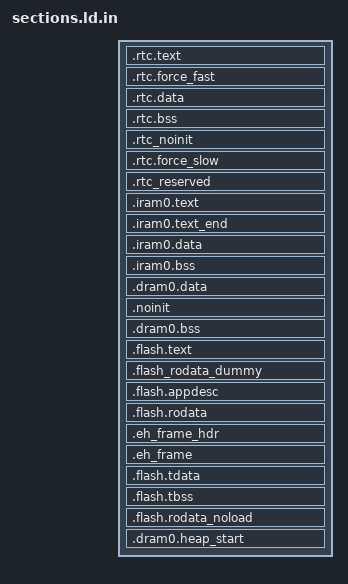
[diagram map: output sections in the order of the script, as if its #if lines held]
/*
 * SPDX-FileCopyrightText: 2022 Espressif Systems (Shanghai) CO LTD
 *
 * SPDX-License-Identifier: Apache-2.0
 */

#include "ld.common"

/* Default entry point */
ENTRY(call_start_cpu0);

SECTIONS
{
  /**
   * RTC fast memory holds RTC wake stub code,
   * including from any source file named rtc_wake_stub*.c
   */
  .rtc.text :
  {
    /* Align the start of RTC code region as per PMP granularity
     * this ensures we do not overwrite the permissions for the previous
     * region (ULP mem) regardless of its end alignment
     */
    ALIGNED_SYMBOL(_esp_pmp_align_size, _rtc_fast_start)
    ALIGNED_SYMBOL(_esp_pmp_align_size, _rtc_text_start)

    *(.rtc.entry.text)

    *(.rtc.literal .rtc.text .rtc.text.*)

    *rtc_wake_stub*.*(.text .text.*)
    *(.rtc_text_end_test)

    /* Align the end of RTC code region as per PMP granularity */
    . = ALIGN(_esp_pmp_align_size);

    _rtc_text_end = ABSOLUTE(.);
  } > lp_ram_seg

  /**
   * This section located in RTC FAST Memory area.
   * It holds data marked with RTC_FAST_ATTR attribute.
   * See the file "esp_attr.h" for more information.
   */
  .rtc.force_fast :
  {
    ALIGNED_SYMBOL(4, _rtc_force_fast_start)

    _coredump_rtc_fast_start = ABSOLUTE(.);
    *(.rtc.fast.coredump .rtc.fast.coredump.*)
    _coredump_rtc_fast_end = ABSOLUTE(.);

    *(.rtc.force_fast .rtc.force_fast.*)

    ALIGNED_SYMBOL(4, _rtc_force_fast_end)
  } > lp_ram_seg

  /**
   * RTC data section holds RTC wake stub
   * data/rodata, including from any source file
   * named rtc_wake_stub*.c and the data marked with
   * RTC_DATA_ATTR, RTC_RODATA_ATTR attributes.
   */
  .rtc.data :
  {
    _rtc_data_start = ABSOLUTE(.);

    _coredump_rtc_start = ABSOLUTE(.);
    *(.rtc.coredump .rtc.coredump.*)
    _coredump_rtc_end = ABSOLUTE(.);
    *(.rtc.data .rtc.data.*)
    *(.rtc.rodata .rtc.rodata.*)

    *rtc_wake_stub*.*(.data .rodata .data.* .rodata.* .srodata.*)

    _rtc_data_end = ABSOLUTE(.);
  } > lp_ram_seg

  /* RTC bss, from any source file named rtc_wake_stub*.c */
  .rtc.bss (NOLOAD) :
  {
    _rtc_bss_start = ABSOLUTE(.);

    *rtc_wake_stub*.*(.bss .bss.* .sbss .sbss.*)
    *rtc_wake_stub*.*(COMMON)

    _rtc_bss_end = ABSOLUTE(.);
    /* part that saves some data for rtc periph module, this part is
       only initialized at power on reset */
    _rtc_bss_rtc_start = ABSOLUTE(.);
    *(.rtc.bss .rtc.bss.*)
    _rtc_bss_rtc_end = ABSOLUTE(.);
  } > lp_ram_seg

  /**
   * This section holds data that should not be initialized at power up
   * and will be retained during deep sleep.
   * User data marked with RTC_NOINIT_ATTR will be placed
   * into this section. See the file "esp_attr.h" for more information.
   */
  .rtc_noinit (NOLOAD):
  {
    ALIGNED_SYMBOL(4, _rtc_noinit_start)

    *(.rtc_noinit .rtc_noinit.*)

    ALIGNED_SYMBOL(4, _rtc_noinit_end)
  } > lp_ram_seg

  /**
   * This section located in RTC SLOW Memory area.
   * It holds data marked with RTC_SLOW_ATTR attribute.
   * See the file "esp_attr.h" for more information.
   */
  .rtc.force_slow :
  {
    ALIGNED_SYMBOL(4, _rtc_force_slow_start)

    *(.rtc.force_slow .rtc.force_slow.*)

    ALIGNED_SYMBOL(4, _rtc_force_slow_end)
  } > lp_ram_seg

  /**
   * This section holds RTC data that should have fixed addresses.
   * The data are not initialized at power-up and are retained during deep
   * sleep.
   */
  .rtc_reserved (NOLOAD):
  {
    ALIGNED_SYMBOL(4, _rtc_reserved_start)

    /**
     * New data can only be added here to ensure existing data are not moved.
     * Because data have adhered to the end of the segment and code is relied
     * on it.
     * >> put new data here <<
     */

    *(.rtc_timer_data_in_rtc_mem .rtc_timer_data_in_rtc_mem.*)
    KEEP(*(.bootloader_data_rtc_mem .bootloader_data_rtc_mem.*))

    _rtc_reserved_end = ABSOLUTE(.);
  } > rtc_reserved_seg

  _rtc_reserved_length = _rtc_reserved_end - _rtc_reserved_start;
  ASSERT((_rtc_reserved_length <= LENGTH(rtc_reserved_seg)),
          "RTC reserved segment data does not fit.")

  /* Get size of rtc slow data based on rtc_data_location alias */
  _rtc_slow_length = (ORIGIN(rtc_slow_seg) == ORIGIN(rtc_data_location))
                        ? (_rtc_force_slow_end - _rtc_data_start)
                        : (_rtc_force_slow_end - _rtc_force_slow_start);

  _rtc_fast_length = (ORIGIN(rtc_slow_seg) == ORIGIN(rtc_data_location))
                        ? (_rtc_force_fast_end - _rtc_fast_start)
                        : (_rtc_noinit_end - _rtc_fast_start);

  ASSERT((_rtc_slow_length <= LENGTH(rtc_slow_seg)),
          "RTC_SLOW segment data does not fit.")

  ASSERT((_rtc_fast_length <= LENGTH(rtc_data_seg)),
          "RTC_FAST segment data does not fit.")

  .iram0.text :
  {
    _iram_start = ABSOLUTE(.);

#if CONFIG_ESP_DEBUG_INCLUDE_OCD_STUB_BINS
    /* Do not move this block! OpenOCD expects this to be at the beginning of IRAM. */
    KEEP(*(.ocd_stub.code));
    KEEP(*(.ocd_stub.tramp));
    . = ALIGN(0x800);
    KEEP(*(.ocd_stub.data));
    KEEP(*(.ocd_stub.bss));
    KEEP(*(.ocd_stub.stack));
    KEEP(*(.ocd_stub.params));
    . = ALIGN(0x1000);
    KEEP(*(.ocd_stub.scratchmem));
    ASSERT(ABSOLUTE(.) == _iram_start + 0x2000, "openocd stub memory must be ended at _iram_start + 0x2000");
#endif

    /* Vectors go to start of IRAM */
    ASSERT(ABSOLUTE(.) % 0x100 == 0, "vector address must be 256 byte aligned");
    KEEP(*(.exception_vectors_table.text));
    KEEP(*(.exception_vectors.text));

    ALIGNED_SYMBOL(4, _invalid_pc_placeholder)

    /* Code marked as running out of IRAM */
    _iram_text_start = ABSOLUTE(.);

    *(.iram1 .iram1.*)
    /* BEGIN generated from ESP-IDF linker fragments, do not edit */
    *libble_app.a:(.high_perf_code_iram1 .high_perf_code_iram1.*)
    *libble_app.a:(.iram_single_sleep .iram_single_sleep.*)
    *components/bt/*.*(.high_perf_code_iram1 .high_perf_code_iram1.*)
    *components/bt/*.*(.iram_single_sleep .iram_single_sleep.*)
    *libclang_rt.builtins.a:_divsf3.*(.literal .literal.* .text .text.*)
    *libclang_rt.builtins.a:restore.*(.literal .literal.* .text .text.*)
    *libclang_rt.builtins.a:save.*(.literal .literal.* .text .text.*)
    *libcoexist.a:(.coexiram .coexiram.*)
    *libcoexist.a:(.coexsleepiram .coexsleepiram.*)
    *components/esp_driver_dma/*esp_dma_utils.*(.literal.esp_dma_merge_aligned_rx_buffers .text.esp_dma_merge_aligned_rx_buffers)
    *components/esp_driver_dma/*esp_dma_utils.*(.literal.esp_dma_split_rx_buffer_to_cache_aligned .text.esp_dma_split_rx_buffer_to_cache_aligned)
    *components/esp_driver_dma/*gdma_link.*(.literal.gdma_link_concat .text.gdma_link_concat)
    *components/esp_driver_dma/*gdma_link.*(.literal.gdma_link_get_buffer .text.gdma_link_get_buffer)
    *components/esp_driver_dma/*gdma_link.*(.literal.gdma_link_get_head_addr .text.gdma_link_get_head_addr)
    *components/esp_driver_dma/*gdma_link.*(.literal.gdma_link_get_length .text.gdma_link_get_length)
    *components/esp_driver_dma/*gdma_link.*(.literal.gdma_link_mount_buffers .text.gdma_link_mount_buffers)
    *components/esp_driver_rmt/*rmt_encoder.*(.literal.rmt_encoder_reset .text.rmt_encoder_reset)
    *components/esp_driver_rmt/*rmt_tx.*(.literal.rmt_encode_check_result .text.rmt_encode_check_result)
    *components/esp_driver_rmt/*rmt_tx.*(.literal.rmt_isr_handle_tx_done .text.rmt_isr_handle_tx_done)
    *components/esp_driver_rmt/*rmt_tx.*(.literal.rmt_isr_handle_tx_loop_end .text.rmt_isr_handle_tx_loop_end)
    *components/esp_driver_rmt/*rmt_tx.*(.literal.rmt_isr_handle_tx_threshold .text.rmt_isr_handle_tx_threshold)
    *components/esp_driver_rmt/*rmt_tx.*(.literal.rmt_tx_default_isr .text.rmt_tx_default_isr)
    *components/esp_driver_rmt/*rmt_tx.*(.literal.rmt_tx_do_transaction .text.rmt_tx_do_transaction)
    *components/esp_driver_rmt/*rmt_tx.*(.literal.rmt_tx_mark_eof .text.rmt_tx_mark_eof)
    *components/esp_hal_ana_conv/*temperature_sensor_hal.*(.literal.temperature_sensor_hal_get_raw_value .text.temperature_sensor_hal_get_raw_value)
    *components/esp_hal_ana_conv/*temperature_sensor_hal.*(.literal.temperature_sensor_hal_i2c_saradc_reg_backup .text.temperature_sensor_hal_i2c_saradc_reg_backup)
    *components/esp_hal_ana_conv/*temperature_sensor_hal.*(.literal.temperature_sensor_hal_i2c_saradc_reg_restore .text.temperature_sensor_hal_i2c_saradc_reg_restore)
    *components/esp_hal_dma/*gdma_hal_ahb_v1.*(.literal.gdma_ahb_hal_append .text.gdma_ahb_hal_append)
    *components/esp_hal_dma/*gdma_hal_ahb_v1.*(.literal.gdma_ahb_hal_clear_intr .text.gdma_ahb_hal_clear_intr)
    *components/esp_hal_dma/*gdma_hal_ahb_v1.*(.literal.gdma_ahb_hal_get_eof_desc_addr .text.gdma_ahb_hal_get_eof_desc_addr)
    *components/esp_hal_dma/*gdma_hal_ahb_v1.*(.literal.gdma_ahb_hal_is_tx_link_switch_event_supported .text.gdma_ahb_hal_is_tx_link_switch_event_supported)
    *components/esp_hal_dma/*gdma_hal_ahb_v1.*(.literal.gdma_ahb_hal_read_intr_status .text.gdma_ahb_hal_read_intr_status)
    *components/esp_hal_dma/*gdma_hal_ahb_v1.*(.literal.gdma_ahb_hal_reset .text.gdma_ahb_hal_reset)
    *components/esp_hal_dma/*gdma_hal_ahb_v1.*(.literal.gdma_ahb_hal_start_with_desc .text.gdma_ahb_hal_start_with_desc)
    *components/esp_hal_dma/*gdma_hal_ahb_v1.*(.literal.gdma_ahb_hal_stop .text.gdma_ahb_hal_stop)
    *components/esp_hal_dma/*gdma_hal_top.*(.literal.gdma_hal_append .text.gdma_hal_append)
    *components/esp_hal_dma/*gdma_hal_top.*(.literal.gdma_hal_clear_intr .text.gdma_hal_clear_intr)
    *components/esp_hal_dma/*gdma_hal_top.*(.literal.gdma_hal_get_eof_desc_addr .text.gdma_hal_get_eof_desc_addr)
    *components/esp_hal_dma/*gdma_hal_top.*(.literal.gdma_hal_is_tx_link_switch_event_supported .text.gdma_hal_is_tx_link_switch_event_supported)
    *components/esp_hal_dma/*gdma_hal_top.*(.literal.gdma_hal_read_intr_status .text.gdma_hal_read_intr_status)
    *components/esp_hal_dma/*gdma_hal_top.*(.literal.gdma_hal_reset .text.gdma_hal_reset)
    *components/esp_hal_dma/*gdma_hal_top.*(.literal.gdma_hal_start_with_desc .text.gdma_hal_start_with_desc)
    *components/esp_hal_dma/*gdma_hal_top.*(.literal.gdma_hal_stop .text.gdma_hal_stop)
    *components/esp_hal_gpio/*gpio_hal.*(.literal.gpio_hal_isolate_in_sleep .text.gpio_hal_isolate_in_sleep)
    *components/esp_hal_gpspi/*spi_hal_iram.*(.literal .literal.* .text .text.*)
    *components/esp_hal_gpspi/*spi_slave_hal_iram.*(.literal .literal.* .text .text.*)
    *components/esp_hal_i2c/*i2c_hal_iram.*(.literal .literal.* .text .text.*)
    *components/esp_hal_ledc/*ledc_hal_iram.*(.literal .literal.* .text .text.*)
    *components/esp_hal_mspi/*spi_flash_encrypt_hal_iram.*(.literal .literal.* .text .text.*)
    *components/esp_hal_mspi/*spi_flash_hal_gpspi.*(.literal .literal.* .text .text.*)
    *components/esp_hal_mspi/*spi_flash_hal_iram.*(.literal .literal.* .text .text.*)
    *components/esp_hal_pmu/*pmu_hal.*(.literal .literal.* .text .text.*)
    *components/esp_hal_regi2c/*.*(.literal .literal.* .text .text.*)
    *components/esp_hal_systimer/*.*(.literal .literal.* .text .text.*)
    *components/esp_hal_timg/*timer_hal.*(.literal.timer_hal_capture_and_get_counter_value .text.timer_hal_capture_and_get_counter_value)
    *components/esp_hal_wdt/*rom_patch.*(.literal .literal.* .text .text.*)
    *components/esp_hw_support/*adc_share_hw_ctrl.*(.literal.adc_apb_periph_claim .text.adc_apb_periph_claim)
    *components/esp_hw_support/*adc_share_hw_ctrl.*(.literal.adc_apb_periph_free .text.adc_apb_periph_free)
    *components/esp_hw_support/*clk_utils.*(.literal .literal.* .text .text.*)
    *components/esp_hw_support/*cpu.*(.literal.esp_cpu_compare_and_set .text.esp_cpu_compare_and_set)
    *components/esp_hw_support/*cpu.*(.literal.esp_cpu_reset .text.esp_cpu_reset)
    *components/esp_hw_support/*cpu.*(.literal.esp_cpu_stall .text.esp_cpu_stall)
    *components/esp_hw_support/*cpu.*(.literal.esp_cpu_unstall .text.esp_cpu_unstall)
    *components/esp_hw_support/*cpu.*(.literal.esp_cpu_wait_for_intr .text.esp_cpu_wait_for_intr)
    *components/esp_hw_support/*esp_clk.*(.literal.esp_clk_private_lock .text.esp_clk_private_lock)
    *components/esp_hw_support/*esp_clk.*(.literal.esp_clk_private_unlock .text.esp_clk_private_unlock)
    *components/esp_hw_support/*esp_clk.*(.literal.esp_clk_slowclk_cal_get .text.esp_clk_slowclk_cal_get)
    *components/esp_hw_support/*esp_clk.*(.literal.esp_clk_slowclk_cal_set .text.esp_clk_slowclk_cal_set)
    *components/esp_hw_support/*esp_clk.*(.literal.esp_rtc_get_time_us .text.esp_rtc_get_time_us)
    *components/esp_hw_support/*esp_clk_tree.*(.literal.esp_clk_tree_enable_power .text.esp_clk_tree_enable_power)
    *components/esp_hw_support/*esp_clk_tree.*(.literal.esp_clk_tree_enable_src .text.esp_clk_tree_enable_src)
    *components/esp_hw_support/*esp_clk_tree.*(.literal.esp_clk_tree_is_power_on .text.esp_clk_tree_is_power_on)
    *components/esp_hw_support/*esp_memory_utils.*(.literal .literal.* .text .text.*)
    *components/esp_hw_support/*mspi_timing_tuning.*(.literal .literal.* .text .text.*)
    *components/esp_hw_support/*periph_ctrl.*(.literal.periph_module_reset .text.periph_module_reset)
    *components/esp_hw_support/*periph_ctrl.*(.literal.periph_rcc_acquire_enter .text.periph_rcc_acquire_enter)
    *components/esp_hw_support/*periph_ctrl.*(.literal.periph_rcc_acquire_exit .text.periph_rcc_acquire_exit)
    *components/esp_hw_support/*periph_ctrl.*(.literal.periph_rcc_enter .text.periph_rcc_enter)
    *components/esp_hw_support/*periph_ctrl.*(.literal.periph_rcc_exit .text.periph_rcc_exit)
    *components/esp_hw_support/*periph_ctrl.*(.literal.periph_rcc_release_enter .text.periph_rcc_release_enter)
    *components/esp_hw_support/*periph_ctrl.*(.literal.periph_rcc_release_exit .text.periph_rcc_release_exit)
    *components/esp_hw_support/*peripheral_domain_pd.*(.literal.peripheral_domain_pd_allowed .text.peripheral_domain_pd_allowed)
    *components/esp_hw_support/*pmu_param.*(.literal.get_act_hp_dbias .text.get_act_hp_dbias)
    *components/esp_hw_support/*pmu_param.*(.literal.get_act_lp_dbias .text.get_act_lp_dbias)
    *components/esp_hw_support/*pmu_sleep.*(.literal .literal.* .text .text.*)
    *components/esp_hw_support/*regi2c_ctrl.*(.literal .literal.* .text .text.*)
    *components/esp_hw_support/*rtc_clk.*(.literal .literal.* .text .text.*)
    *components/esp_hw_support/*rtc_time.*(.literal .literal.* .text .text.*)
    *components/esp_hw_support/*sar_periph_ctrl.*(.literal.adc_reset_lock_acquire .text.adc_reset_lock_acquire)
    *components/esp_hw_support/*sar_periph_ctrl.*(.literal.adc_reset_lock_release .text.adc_reset_lock_release)
    *components/esp_hw_support/*sar_periph_ctrl.*(.literal.sar_periph_ctrl_adc_reset .text.sar_periph_ctrl_adc_reset)
    *components/esp_hw_support/*sar_periph_ctrl.*(.literal.sar_periph_ctrl_power_disable .text.sar_periph_ctrl_power_disable)
    *components/esp_hw_support/*sar_periph_ctrl.*(.literal.sar_periph_ctrl_power_enable .text.sar_periph_ctrl_power_enable)
    *components/esp_hw_support/*sar_periph_ctrl_common.*(.literal.regi2c_saradc_disable .text.regi2c_saradc_disable)
    *components/esp_hw_support/*sar_periph_ctrl_common.*(.literal.regi2c_saradc_enable .text.regi2c_saradc_enable)
    *components/esp_hw_support/*sar_tsens_ctrl.*(.literal.temp_sensor_get_raw_value .text.temp_sensor_get_raw_value)
    *components/esp_hw_support/*sar_tsens_ctrl.*(.literal.temperature_sensor_power_acquire .text.temperature_sensor_power_acquire)
    *components/esp_hw_support/*sar_tsens_ctrl.*(.literal.temperature_sensor_power_release .text.temperature_sensor_power_release)
    *components/esp_hw_support/*sleep_cache.*(.literal .literal.* .text .text.*)
    *components/esp_hw_support/*sleep_clock.*(.literal.clock_domain_pd_allowed .text.clock_domain_pd_allowed)
    *components/esp_hw_support/*sleep_console.*(.literal .literal.* .text .text.*)
    *components/esp_hw_support/*sleep_cpu.*(.literal.cpu_domain_pd_allowed .text.cpu_domain_pd_allowed)
    *components/esp_hw_support/*sleep_modem.*(.literal.modem_domain_pd_allowed .text.modem_domain_pd_allowed)
    *components/esp_hw_support/*sleep_modem.*(.literal.periph_inform_out_light_sleep_overhead .text.periph_inform_out_light_sleep_overhead)
    *components/esp_hw_support/*sleep_modem.*(.literal.sleep_modem_reject_triggers .text.sleep_modem_reject_triggers)
    *components/esp_hw_support/*sleep_modes.*(.literal.esp_light_sleep_start .text.esp_light_sleep_start)
    *components/esp_hw_support/*sleep_modes.*(.literal.esp_sleep_enable_timer_wakeup .text.esp_sleep_enable_timer_wakeup)
    *components/esp_hw_support/*sleep_mspi.*(.literal .literal.* .text .text.*)
    *components/esp_hw_support/*systimer.*(.literal .literal.* .text .text.*)
    *components/esp_libc/*abort.*(.literal .literal.* .text .text.*)
    *components/esp_libc/*assert.*(.literal .literal.* .text .text.*)
    *components/esp_libc/*esp_time_impl.*(.literal.esp_set_time_from_rtc .text.esp_set_time_from_rtc)
    *components/esp_libc/*esp_time_impl.*(.literal.esp_time_impl_get_boot_time .text.esp_time_impl_get_boot_time)
    *components/esp_libc/*esp_time_impl.*(.literal.esp_time_impl_set_boot_time .text.esp_time_impl_set_boot_time)
    *components/esp_libc/*heap.*(.literal .literal.* .text .text.*)
    *components/esp_libc/*memcmp.*(.literal .literal.* .text .text.*)
    *components/esp_libc/*memcpy.*(.literal .literal.* .text .text.*)
    *components/esp_libc/*memmove.*(.literal .literal.* .text .text.*)
    *components/esp_libc/*stdatomic.*(.literal .literal.* .text .text.*)
    *components/esp_libc/*strcmp.*(.literal .literal.* .text .text.*)
    *components/esp_libc/*strcpy.*(.literal .literal.* .text .text.*)
    *components/esp_libc/*strncmp.*(.literal .literal.* .text .text.*)
    *components/esp_libc/*strncpy.*(.literal .literal.* .text .text.*)
    *components/esp_mm/*esp_cache_msync.*(.literal .literal.* .text .text.*)
    *components/esp_mm/*esp_cache_utils.*(.literal .literal.* .text .text.*)
    *components/esp_phy/*phy_init.*(.literal.esp_phy_disable .text.esp_phy_disable)
    *components/esp_phy/*phy_init.*(.literal.esp_phy_enable .text.esp_phy_enable)
    *components/esp_phy/*phy_init.*(.literal.esp_wifi_bt_power_domain_off .text.esp_wifi_bt_power_domain_off)
    *components/esp_phy/*phy_override.*(.literal.phy_get_tsens_value .text.phy_get_tsens_value)
    *components/esp_pm/*pm_impl.*(.literal.esp_pm_impl_get_cpu_freq .text.esp_pm_impl_get_cpu_freq)
    *components/esp_rom/*esp_rom_print.*(.literal .literal.* .text .text.*)
    *components/esp_rom/*esp_rom_spiflash.*(.literal .literal.* .text .text.*)
    *components/esp_rom/*esp_rom_sys.*(.literal .literal.* .text .text.*)
    *components/esp_system/*esp_err.*(.literal .literal.* .text .text.*)
    *components/esp_system/*image_process.*(.literal .literal.* .text .text.*)
    *components/esp_system/*ubsan.*(.literal .literal.* .text .text.*)
    *components/esp_timer/*esp_timer_impl_common.*(.literal.esp_timer_impl_lock .text.esp_timer_impl_lock)
    *components/esp_timer/*esp_timer_impl_common.*(.literal.esp_timer_impl_unlock .text.esp_timer_impl_unlock)
    *components/esp_timer/*esp_timer_impl_systimer.*(.literal.esp_timer_impl_advance .text.esp_timer_impl_advance)
    *components/esp_timer/*esp_timer_impl_systimer.*(.literal.esp_timer_impl_set .text.esp_timer_impl_set)
    *components/esp_wifi/*esp_adapter.*(.literal.coex_pti_get_wrapper .text.coex_pti_get_wrapper)
    *components/esp_wifi/*esp_adapter.*(.literal.wifi_clock_disable_wrapper .text.wifi_clock_disable_wrapper)
    *components/esp_wifi/*esp_adapter.*(.literal.wifi_clock_enable_wrapper .text.wifi_clock_enable_wrapper)
    *components/freertos/*port_systick.*(.literal .literal.* .text .text.*)
    *components/freertos/*portasm.*(.literal .literal.* .text .text.*)
    *libgcc.a:_divsf3.*(.literal .literal.* .text .text.*)
    *libgcc.a:lib2funcs.*(.literal .literal.* .text .text.*)
    *libgcc.a:save-restore.*(.literal .literal.* .text .text.*)
    *libgcov.a:(.literal .literal.* .text .text.*)
    *components/hal/*cache_hal.*(.literal .literal.* .text .text.*)
    *components/hal/*mmu_hal.*(.literal .literal.* .text .text.*)
    *components/heap/*multi_heap.*(.literal.multi_heap_aligned_alloc_offs .text.multi_heap_aligned_alloc_offs)
    *components/heap/*multi_heap.*(.literal.multi_heap_get_full_block_size .text.multi_heap_get_full_block_size)
    *components/ieee802154/*esp_ieee802154.*(.literal.esp_ieee802154_enh_ack_generator .text.esp_ieee802154_enh_ack_generator)
    *components/ieee802154/*esp_ieee802154.*(.literal.esp_ieee802154_get_extended_address .text.esp_ieee802154_get_extended_address)
    *components/ieee802154/*esp_ieee802154.*(.literal.esp_ieee802154_get_recent_lqi .text.esp_ieee802154_get_recent_lqi)
    *components/ieee802154/*esp_ieee802154.*(.literal.esp_ieee802154_get_recent_rssi .text.esp_ieee802154_get_recent_rssi)
    *components/ieee802154/*esp_ieee802154.*(.literal.esp_ieee802154_receive .text.esp_ieee802154_receive)
    *components/ieee802154/*esp_ieee802154.*(.literal.esp_ieee802154_receive_at .text.esp_ieee802154_receive_at)
    *components/ieee802154/*esp_ieee802154.*(.literal.esp_ieee802154_set_transmit_security .text.esp_ieee802154_set_transmit_security)
    *components/ieee802154/*esp_ieee802154.*(.literal.esp_ieee802154_transmit .text.esp_ieee802154_transmit)
    *components/ieee802154/*esp_ieee802154.*(.literal.esp_ieee802154_transmit_at .text.esp_ieee802154_transmit_at)
    *components/ieee802154/*esp_ieee802154_ack.*(.literal.ieee802154_ack_config_pending_bit .text.ieee802154_ack_config_pending_bit)
    *components/ieee802154/*esp_ieee802154_dev.*(.literal.ieee802154_finish_receive_at .text.ieee802154_finish_receive_at)
    *components/ieee802154/*esp_ieee802154_dev.*(.literal.ieee802154_get_recent_lqi .text.ieee802154_get_recent_lqi)
    *components/ieee802154/*esp_ieee802154_dev.*(.literal.ieee802154_get_recent_rssi .text.ieee802154_get_recent_rssi)
    *components/ieee802154/*esp_ieee802154_dev.*(.literal.ieee802154_isr .text.ieee802154_isr)
    *components/ieee802154/*esp_ieee802154_dev.*(.literal.ieee802154_receive .text.ieee802154_receive)
    *components/ieee802154/*esp_ieee802154_dev.*(.literal.ieee802154_receive_at .text.ieee802154_receive_at)
    *components/ieee802154/*esp_ieee802154_dev.*(.literal.ieee802154_rx_frame_info_update .text.ieee802154_rx_frame_info_update)
    *components/ieee802154/*esp_ieee802154_dev.*(.literal.ieee802154_start_receive_at .text.ieee802154_start_receive_at)
    *components/ieee802154/*esp_ieee802154_dev.*(.literal.ieee802154_transmit .text.ieee802154_transmit)
    *components/ieee802154/*esp_ieee802154_dev.*(.literal.ieee802154_transmit_at .text.ieee802154_transmit_at)
    *components/ieee802154/*esp_ieee802154_dev.*(.literal.set_next_rx_buffer .text.set_next_rx_buffer)
    *components/ieee802154/*esp_ieee802154_dev.*(.literal.stop_cca .text.stop_cca)
    *components/ieee802154/*esp_ieee802154_dev.*(.literal.stop_current_operation .text.stop_current_operation)
    *components/ieee802154/*esp_ieee802154_dev.*(.literal.stop_ed .text.stop_ed)
    *components/ieee802154/*esp_ieee802154_dev.*(.literal.stop_rx .text.stop_rx)
    *components/ieee802154/*esp_ieee802154_dev.*(.literal.stop_rx_ack .text.stop_rx_ack)
    *components/ieee802154/*esp_ieee802154_dev.*(.literal.stop_tx .text.stop_tx)
    *components/ieee802154/*esp_ieee802154_dev.*(.literal.stop_tx_ack .text.stop_tx_ack)
    *components/ieee802154/*esp_ieee802154_dev.*(.literal.stop_tx_cca .text.stop_tx_cca)
    *components/ieee802154/*esp_ieee802154_event.*(.literal.ieee802154_inner_energy_detect_done .text.ieee802154_inner_energy_detect_done)
    *components/ieee802154/*esp_ieee802154_event.*(.literal.ieee802154_inner_enh_ack_generator .text.ieee802154_inner_enh_ack_generator)
    *components/ieee802154/*esp_ieee802154_event.*(.literal.ieee802154_inner_receive_done .text.ieee802154_inner_receive_done)
    *components/ieee802154/*esp_ieee802154_event.*(.literal.ieee802154_inner_receive_sfd_done .text.ieee802154_inner_receive_sfd_done)
    *components/ieee802154/*esp_ieee802154_event.*(.literal.ieee802154_inner_transmit_done .text.ieee802154_inner_transmit_done)
    *components/ieee802154/*esp_ieee802154_event.*(.literal.ieee802154_inner_transmit_failed .text.ieee802154_inner_transmit_failed)
    *components/ieee802154/*esp_ieee802154_event.*(.literal.ieee802154_inner_transmit_sfd_done .text.ieee802154_inner_transmit_sfd_done)
    *components/ieee802154/*esp_ieee802154_frame.*(.literal.ieee802154_frame_get_dest_panid .text.ieee802154_frame_get_dest_panid)
    *components/ieee802154/*esp_ieee802154_frame.*(.literal.ieee802154_frame_get_dst_addr .text.ieee802154_frame_get_dst_addr)
    *components/ieee802154/*esp_ieee802154_frame.*(.literal.ieee802154_frame_get_security_field_len .text.ieee802154_frame_get_security_field_len)
    *components/ieee802154/*esp_ieee802154_frame.*(.literal.ieee802154_frame_get_security_payload_offset .text.ieee802154_frame_get_security_payload_offset)
    *components/ieee802154/*esp_ieee802154_frame.*(.literal.ieee802154_frame_get_src_addr .text.ieee802154_frame_get_src_addr)
    *components/ieee802154/*esp_ieee802154_frame.*(.literal.ieee802154_frame_get_src_panid .text.ieee802154_frame_get_src_panid)
    *components/ieee802154/*esp_ieee802154_frame.*(.literal.ieee802154_frame_is_security_enabled .text.ieee802154_frame_is_security_enabled)
    *components/ieee802154/*esp_ieee802154_frame.*(.literal.ieee802154_frame_security_header_offset .text.ieee802154_frame_security_header_offset)
    *components/ieee802154/*esp_ieee802154_frame.*(.literal.ieee802154_is_data_request .text.ieee802154_is_data_request)
    *components/ieee802154/*esp_ieee802154_frame.*(.literal.is_dst_panid_present .text.is_dst_panid_present)
    *components/ieee802154/*esp_ieee802154_frame.*(.literal.is_src_panid_present .text.is_src_panid_present)
    *components/ieee802154/*esp_ieee802154_pib.*(.literal.ieee802154_pib_get_pending_mode .text.ieee802154_pib_get_pending_mode)
    *components/ieee802154/*esp_ieee802154_pib.*(.literal.ieee802154_pib_get_rx_when_idle .text.ieee802154_pib_get_rx_when_idle)
    *components/ieee802154/*esp_ieee802154_pib.*(.literal.ieee802154_pib_update .text.ieee802154_pib_update)
    *components/ieee802154/*esp_ieee802154_pib.*(.literal.ieee802154_txpower_convert .text.ieee802154_txpower_convert)
    *components/ieee802154/*esp_ieee802154_sec.*(.literal.ieee802154_sec_clear .text.ieee802154_sec_clear)
    *components/ieee802154/*esp_ieee802154_sec.*(.literal.ieee802154_transmit_security_config .text.ieee802154_transmit_security_config)
    *components/ieee802154/*esp_ieee802154_timer.*(.literal.ieee802154_timer0_fire_at .text.ieee802154_timer0_fire_at)
    *components/ieee802154/*esp_ieee802154_timer.*(.literal.ieee802154_timer0_fire_at_with_callback .text.ieee802154_timer0_fire_at_with_callback)
    *components/ieee802154/*esp_ieee802154_timer.*(.literal.ieee802154_timer0_set_callback .text.ieee802154_timer0_set_callback)
    *components/ieee802154/*esp_ieee802154_timer.*(.literal.ieee802154_timer0_set_threshold .text.ieee802154_timer0_set_threshold)
    *components/ieee802154/*esp_ieee802154_timer.*(.literal.ieee802154_timer0_start .text.ieee802154_timer0_start)
    *components/ieee802154/*esp_ieee802154_timer.*(.literal.ieee802154_timer0_stop .text.ieee802154_timer0_stop)
    *components/ieee802154/*esp_ieee802154_timer.*(.literal.ieee802154_timer1_fire_at .text.ieee802154_timer1_fire_at)
    *components/ieee802154/*esp_ieee802154_timer.*(.literal.ieee802154_timer1_fire_at_with_callback .text.ieee802154_timer1_fire_at_with_callback)
    *components/ieee802154/*esp_ieee802154_timer.*(.literal.ieee802154_timer1_set_callback .text.ieee802154_timer1_set_callback)
    *components/ieee802154/*esp_ieee802154_timer.*(.literal.ieee802154_timer1_set_threshold .text.ieee802154_timer1_set_threshold)
    *components/ieee802154/*esp_ieee802154_timer.*(.literal.ieee802154_timer1_start .text.ieee802154_timer1_start)
    *components/ieee802154/*esp_ieee802154_timer.*(.literal.ieee802154_timer1_stop .text.ieee802154_timer1_stop)
    *components/ieee802154/*esp_ieee802154_timer.*(.literal.isr_handle_timer0_done .text.isr_handle_timer0_done)
    *components/ieee802154/*esp_ieee802154_timer.*(.literal.isr_handle_timer1_done .text.isr_handle_timer1_done)
    *components/ieee802154/*esp_ieee802154_util.*(.literal.ieee802154_channel_to_freq .text.ieee802154_channel_to_freq)
    *components/ieee802154/*esp_ieee802154_util.*(.literal.ieee802154_etm_channel_clear .text.ieee802154_etm_channel_clear)
    *components/log/*log.*(.literal .literal.* .text .text.*)
    *components/log/*log_format_text.*(.literal .literal.* .text .text.*)
    *components/log/*log_lock.*(.literal .literal.* .text .text.*)
    *components/log/*log_print.*(.literal .literal.* .text .text.*)
    *components/log/*log_timestamp.*(.literal.esp_log_early_timestamp .text.esp_log_early_timestamp)
    *components/log/*log_timestamp_common.*(.literal .literal.* .text .text.*)
    *components/log/*util.*(.literal .literal.* .text .text.*)
    *libnet80211.a:(.wifi0iram .wifi0iram.*)
    *libnet80211.a:(.wifiextrairam .wifiextrairam.*)
    *libnet80211.a:(.wifirxiram .wifirxiram.*)
    *libnet80211.a:(.wifislpiram .wifislpiram.*)
    *libnet80211.a:(.wifislprxiram .wifislprxiram.*)
    *libpp.a:(.wifi0iram .wifi0iram.*)
    *libpp.a:(.wifiextrairam .wifiextrairam.*)
    *libpp.a:(.wifiorslpiram .wifiorslpiram.*)
    *libpp.a:(.wifirxiram .wifirxiram.*)
    *libpp.a:(.wifislpiram .wifislpiram.*)
    *libpp.a:(.wifislprxiram .wifislprxiram.*)
    *components/riscv/*interrupt.*(.text .text._global_interrupt_handler .text.intr_get_item.part.0 .text.intr_handler_get_arg)
    *components/riscv/*rv_utils.*(.literal .literal.* .text .text.*)
    *components/riscv/*vectors.*(.literal .literal.* .text .text.*)
    *librtc.a:(.literal .literal.* .text .text.*)
    *components/soc/*lldesc.*(.literal .literal.* .text .text.*)
    *components/spi_flash/*esp_flash_api.*(.literal.check_chip_pointer_default .text.check_chip_pointer_default)
    *components/spi_flash/*esp_flash_api.*(.literal.detect_spi_flash_chip .text.detect_spi_flash_chip)
    *components/spi_flash/*esp_flash_api.*(.literal.esp_flash_chip_driver_initialized .text.esp_flash_chip_driver_initialized)
    *components/spi_flash/*esp_flash_api.*(.literal.esp_flash_erase_chip .text.esp_flash_erase_chip)
    *components/spi_flash/*esp_flash_api.*(.literal.esp_flash_erase_region .text.esp_flash_erase_region)
    *components/spi_flash/*esp_flash_api.*(.literal.esp_flash_get_chip_write_protect .text.esp_flash_get_chip_write_protect)
    *components/spi_flash/*esp_flash_api.*(.literal.esp_flash_get_io_mode .text.esp_flash_get_io_mode)
    *components/spi_flash/*esp_flash_api.*(.literal.esp_flash_get_physical_size .text.esp_flash_get_physical_size)
    *components/spi_flash/*esp_flash_api.*(.literal.esp_flash_get_protected_region .text.esp_flash_get_protected_region)
    *components/spi_flash/*esp_flash_api.*(.literal.esp_flash_get_size .text.esp_flash_get_size)
    *components/spi_flash/*esp_flash_api.*(.literal.esp_flash_init .text.esp_flash_init)
    *components/spi_flash/*esp_flash_api.*(.literal.esp_flash_init_main .text.esp_flash_init_main)
    *components/spi_flash/*esp_flash_api.*(.literal.esp_flash_is_quad_mode .text.esp_flash_is_quad_mode)
    *components/spi_flash/*esp_flash_api.*(.literal.esp_flash_read .text.esp_flash_read)
    *components/spi_flash/*esp_flash_api.*(.literal.esp_flash_read_encrypted .text.esp_flash_read_encrypted)
    *components/spi_flash/*esp_flash_api.*(.literal.esp_flash_set_chip_write_protect .text.esp_flash_set_chip_write_protect)
    *components/spi_flash/*esp_flash_api.*(.literal.esp_flash_set_io_mode .text.esp_flash_set_io_mode)
    *components/spi_flash/*esp_flash_api.*(.literal.esp_flash_set_protected_region .text.esp_flash_set_protected_region)
    *components/spi_flash/*esp_flash_api.*(.literal.esp_flash_write .text.esp_flash_write)
    *components/spi_flash/*esp_flash_api.*(.literal.esp_flash_write_encrypted .text.esp_flash_write_encrypted)
    *components/spi_flash/*esp_flash_api.*(.literal.flash_end_flush_cache .text.flash_end_flush_cache)
    *components/spi_flash/*esp_flash_api.*(.literal.read_unique_id .text.read_unique_id)
    *components/spi_flash/*esp_flash_api.*(.literal.spiflash_end_default .text.spiflash_end_default)
    *components/spi_flash/*esp_flash_api.*(.literal.spiflash_start_core .text.spiflash_start_core)
    *components/spi_flash/*esp_flash_api.*(.literal.spiflash_start_prog .text.spiflash_start_prog)
    *components/spi_flash/*flash_brownout_hook.*(.literal .literal.* .text .text.*)
    *components/spi_flash/*memspi_host_driver.*(.literal .literal.* .text .text.*)
    *components/spi_flash/*spi_flash_chip_boya.*(.literal .literal.* .text .text.*)
    *components/spi_flash/*spi_flash_chip_gd.*(.literal .literal.* .text .text.*)
    *components/spi_flash/*spi_flash_chip_generic.*(.literal .literal.* .text .text.*)
    *components/spi_flash/*spi_flash_chip_issi.*(.literal .literal.* .text .text.*)
    *components/spi_flash/*spi_flash_chip_mxic.*(.literal .literal.* .text .text.*)
    *components/spi_flash/*spi_flash_chip_th.*(.literal .literal.* .text .text.*)
    *components/spi_flash/*spi_flash_chip_winbond.*(.literal .literal.* .text .text.*)
    *components/spi_flash/*spi_flash_os_func_app.*(.literal.delay_us .text.delay_us)
    *components/spi_flash/*spi_flash_os_func_app.*(.literal.get_buffer_malloc .text.get_buffer_malloc)
    *components/spi_flash/*spi_flash_os_func_app.*(.literal.main_flash_region_protected .text.main_flash_region_protected)
    *components/spi_flash/*spi_flash_os_func_app.*(.literal.release_buffer_malloc .text.release_buffer_malloc)
    *components/spi_flash/*spi_flash_os_func_app.*(.literal.spi23_end .text.spi23_end)
    *components/spi_flash/*spi_flash_os_func_app.*(.literal.spi23_start .text.spi23_start)
    *components/spi_flash/*spi_flash_os_func_app.*(.literal.spi_flash_os_check_yield .text.spi_flash_os_check_yield)
    *components/spi_flash/*spi_flash_os_func_app.*(.literal.spi_flash_os_yield .text.spi_flash_os_yield)
    *components/spi_flash/*spi_flash_os_func_noos.*(.literal.delay_us .text.delay_us)
    *components/spi_flash/*spi_flash_os_func_noos.*(.literal.esp_flash_app_disable_os_functions .text.esp_flash_app_disable_os_functions)
    *components/spi_flash/*spi_flash_os_func_noos.*(.literal.get_temp_buffer_not_supported .text.get_temp_buffer_not_supported)
    *components/spi_flash/*spi_flash_wrap.*(.literal .literal.* .text .text.*)
    /* END generated from ESP-IDF linker fragments */
    /* BLE controller code placed in IRAM (linker_esp_ble_controller.lf) */
    *(.high_perf_code_iram1 .high_perf_code_iram1.*)
    *(.iram_single_sleep .iram_single_sleep.*)

    /* parts of RIOT that should run in IRAM */
    *core/*(.literal .text .literal.* .text.*)
    *core_lib/*(.literal .text .literal.* .text.*)
    *esp_common_periph/flash.*(.literal .text .literal.* .text.*)
    *esp_common/thread_arch.*(.literal .text .literal.* .text.*)
    *esp_freertos_common/*(.literal .text .literal.* .text.*)
    *isrpipe/*(.literal .text .literal.* .text.*)
    *stdio/stdio.*(.literal .text .literal.* .text.*) 
    *stdio_*/stdio*(.literal .text .literal.* .text.*) 
    *syscalls.*(.literal .text .literal.* .text.*)
    *tsrb/*(.literal .text .literal.* .text.*)

    /* parts of ESP-IDF that should run in IRAM */
    /* find components/ -type f -name linker.lf -exec grep "(noflash)" {} \; -print */
    /* find components/ -type f -name linker.lf -exec grep "(noflash_text)" {} \; -print */
    *components/app_trace/app_trace.*(.literal .literal.* .text .text.*)
    *components/app_trace/app_trace_util.*(.literal .literal.* .text .text.*)
    *components/app_trace/port/port_uart.*(.literal .literal.* .text .text.*)
    *components/esp_driver_gptimer/src/gptimer.*(.literal.gptimer_default_isr .text.gptimer_default_isr)
    *components/esp_event/default_event_loop.*(.literal.esp_event_isr_post .text.esp_event_isr_post)
    *components/esp_event/esp_event.*(.literal.esp_event_isr_post_to .text.esp_event_isr_post_to)
    *components/esp_hw_support/cpu.*(.literal.esp_cpu_compare_and_set .text.esp_cpu_compare_and_set)
    *components/esp_hw_support/cpu.*(.literal.esp_cpu_reset .text.esp_cpu_reset)
    *components/esp_hw_support/cpu.*(.literal.esp_cpu_stall .text.esp_cpu_stall)
    *components/esp_hw_support/cpu.*(.literal.esp_cpu_unstall .text.esp_cpu_unstall)
    *components/esp_hw_support/cpu.*(.literal.esp_cpu_wait_for_intr .text.esp_cpu_wait_for_intr)
    *components/esp_hw_support/esp_memory_utils.*(.literal .literal.* .text .text.*)
    *components/esp_hw_support/gdma.*(.literal.gdma_append .text.gdma_append)
    *components/esp_hw_support/gdma.*(.literal.gdma_default_rx_isr .text.gdma_default_rx_isr)
    *components/esp_hw_support/gdma.*(.literal.gdma_default_tx_isr .text.gdma_default_tx_isr)
    *components/esp_hw_support/gdma.*(.literal.gdma_reset .text.gdma_reset)
    *components/esp_hw_support/gdma.*(.literal.gdma_start .text.gdma_start)
    *components/esp_hw_support/gdma.*(.literal.gdma_stop .text.gdma_stop)
    *components/esp_hw_support/mspi_timing_tuning.*(.literal .literal.* .text .text.*)
    *components/esp_hw_support/periph_ctrl.*(.literal.periph_module_reset .text.periph_module_reset)
    *components/esp_hw_support/periph_ctrl.*(.literal.wifi_module_disable .text.wifi_module_disable)
    *components/esp_hw_support/periph_ctrl.*(.literal.wifi_module_enable .text.wifi_module_enable)
    *components/esp_hw_support/*/pmu_sleep.*(.literal .literal.* .text .text.*)
    *components/esp_hw_support/*/rtc_clk.*(.literal .literal.* .text .text.*)
    *components/esp_hw_support/*/rtc_time.*(.literal .literal.* .text .text.*)
    *components/esp_hw_support/*/sar_periph_ctrl.*(.literal.sar_periph_ctrl_power_enable .text.sar_periph_ctrl_power_enable)
    *components/esp_hw_support/sleep_console.*(.literal .literal.* .text .text.*)
    *components/esp_hw_support/*/systimer.*(.literal .literal.* .text .text.*)
    *components/esp_mm/esp_cache.*(.literal .literal.* .text .text.*)
    *components/esp_phy/*/phy_init.*(.literal.esp_phy_disable .text.esp_phy_disable)
    *components/esp_phy/*/phy_init.*(.literal.esp_phy_enable .text.esp_phy_enable)
    *components/esp_phy/*/phy_init.*(.literal.esp_wifi_bt_power_domain_off .text.esp_wifi_bt_power_domain_off)
    *components/esp_ringbuf/*(.literal .literal.* .text .text.*)
    *components/esp_rom/patches/esp_rom_print.*(.literal .literal.* .text .text.*)
    *components/esp_rom/patches/esp_rom_spiflash.*(.literal .literal.* .text .text.*)
    *components/esp_rom/patches/esp_rom_sys.*(.literal .literal.* .text .text.*)
    *components/esp_rom/patches/esp_rom_systimer.*(.literal .literal.* .text .text.*)
    *components/esp_rom/patches/esp_rom_tlsf.*(.literal .literal.* .text .text.*)
    *components/esp_rom/patches/esp_rom_wdt.*(.literal .literal.* .text .text.*)
    *components/esp_system/esp_err.*(.literal .literal.* .text .text.*)
    *components/esp_system/esp_system_chip.*(.literal.esp_system_abort .text.esp_system_abort)
    *components/esp_system/image_process.*(.literal .literal.* .text .text.*)
    *components/esp_system/ubsan.*(.literal .literal.* .text .text.*)
    *components/esp_wifi/*/esp_adapter.*(.literal.coex_pti_get_wrapper .text.coex_pti_get_wrapper)
    *components/esp_wifi/*/esp_adapter.*(.literal.wifi_clock_disable_wrapper .text.wifi_clock_disable_wrapper)
    *components/esp_wifi/*/esp_adapter.*(.literal.wifi_clock_enable_wrapper .text.wifi_clock_enable_wrapper)
    *components/esp_wifi/src/wifi_netif.*(.literal.wifi_sta_receive .text.wifi_sta_receive)
    *components/esp_wifi/src/wifi_netif.*(.literal.wifi_transmit_wrap .text.wifi_transmit_wrap)

    *libclang_rt.builtins.a:_divsf3.*(.literal .literal.* .text .text.*)
    *libclang_rt.builtins.a:restore.*(.literal .literal.* .text .text.*)
    *libclang_rt.builtins.a:save.*(.literal .literal.* .text .text.*)
    *libcoexist.a:(.coexiram .coexiram.*)
    *libcoexist.a:(.coexsleepiram .coexsleepiram.*)
    *libgcc.a:_divsf3.*(.literal .literal.* .text .text.*)
    *libgcc.a:lib2funcs.*(.literal .literal.* .text .text.*)
    *libgcc.a:save-restore.*(.literal .literal.* .text .text.*)
    *libgcov.a:(.literal .literal.* .text .text.*)

    *components/hal/cache_hal.*(.literal .literal.* .text .text.*)
    *components/hal/gdma_hal_ahb_v1.*(.literal.gdma_ahb_hal_append .text.gdma_ahb_hal_append)
    *components/hal/gdma_hal_ahb_v1.*(.literal.gdma_ahb_hal_clear_intr .text.gdma_ahb_hal_clear_intr)
    *components/hal/gdma_hal_ahb_v1.*(.literal.gdma_ahb_hal_get_eof_desc_addr .text.gdma_ahb_hal_get_eof_desc_addr)
    *components/hal/gdma_hal_ahb_v1.*(.literal.gdma_ahb_hal_read_intr_status .text.gdma_ahb_hal_read_intr_status)
    *components/hal/gdma_hal_ahb_v1.*(.literal.gdma_ahb_hal_reset .text.gdma_ahb_hal_reset)
    *components/hal/gdma_hal_ahb_v1.*(.literal.gdma_ahb_hal_start_with_desc .text.gdma_ahb_hal_start_with_desc)
    *components/hal/gdma_hal_ahb_v1.*(.literal.gdma_ahb_hal_stop .text.gdma_ahb_hal_stop)
    *components/hal/gdma_hal_top.*(.literal.gdma_hal_append .text.gdma_hal_append)
    *components/hal/gdma_hal_top.*(.literal.gdma_hal_clear_intr .text.gdma_hal_clear_intr)
    *components/hal/gdma_hal_top.*(.literal.gdma_hal_get_eof_desc_addr .text.gdma_hal_get_eof_desc_addr)
    *components/hal/gdma_hal_top.*(.literal.gdma_hal_read_intr_status .text.gdma_hal_read_intr_status)
    *components/hal/gdma_hal_top.*(.literal.gdma_hal_reset .text.gdma_hal_reset)
    *components/hal/gdma_hal_top.*(.literal.gdma_hal_start_with_desc .text.gdma_hal_start_with_desc)
    *components/hal/gdma_hal_top.*(.literal.gdma_hal_stop .text.gdma_hal_stop)
    *components/hal/gpio_hal.*(.literal.gpio_hal_isolate_in_sleep .text.gpio_hal_isolate_in_sleep)
    *components/hal/i2c_hal_iram.*(.literal .literal.* .text .text.*)
    *components/hal/ledc_hal_iram.*(.literal .literal.* .text .text.*)
    *components/hal/mmu_hal.*(.literal .literal.* .text .text.*)
    *components/hal/pmu_hal.*(.literal .literal.* .text .text.*)
    *components/hal/spi_flash_encrypt_hal_iram.*(.literal .literal.* .text .text.*)
    *components/hal/spi_flash_hal_gpspi.*(.literal .literal.* .text .text.*)
    *components/hal/spi_flash_hal_iram.*(.literal .literal.* .text .text.*)
    *components/hal/spi_hal_iram.*(.literal .literal.* .text .text.*)
    *components/hal/spi_slave_hal_iram.*(.literal .literal.* .text .text.*)
    *components/hal/timer_hal.*(.literal.timer_hal_capture_and_get_counter_value .text.timer_hal_capture_and_get_counter_value)
    *components/hal/wdt_hal_iram.*(.literal .literal.* .text .text.*)
    *components/heap/multi_heap.*(.literal._multi_heap_lock .text._multi_heap_lock)
    *components/heap/multi_heap.*(.literal._multi_heap_unlock .text._multi_heap_unlock)
    *components/heap/multi_heap.*(.literal.multi_heap_aligned_alloc_offs .text.multi_heap_aligned_alloc_offs)
    *components/heap/multi_heap.*(.literal.multi_heap_in_rom_init .text.multi_heap_in_rom_init)

    *libnet80211.a:(.wifi0iram .wifi0iram.*)
    *libnet80211.a:(.wifiextrairam .wifiextrairam.*)
    *libnet80211.a:(.wifirxiram .wifirxiram.*)
    *libnet80211.a:(.wifislpiram .wifislpiram.*)
    *libnet80211.a:(.wifislprxiram .wifislprxiram.*)

    *libieee802154.a:esp_ieee802154_ack.*(.literal.ieee802154_ack_config_pending_bit .text.ieee802154_ack_config_pending_bit)
    *libieee802154.a:esp_ieee802154_dev.*(.literal.ieee802154_isr .text.ieee802154_isr)
    *libieee802154.a:esp_ieee802154_dev.*(.literal.ieee802154_rx_frame_info_update .text.ieee802154_rx_frame_info_update)
    *libieee802154.a:esp_ieee802154_event.*(.literal.ieee802154_inner_energy_detect_done .text.ieee802154_inner_energy_detect_done)
    *libieee802154.a:esp_ieee802154_event.*(.literal.ieee802154_inner_enh_ack_generator .text.ieee802154_inner_enh_ack_generator)
    *libieee802154.a:esp_ieee802154_event.*(.literal.ieee802154_inner_receive_done .text.ieee802154_inner_receive_done)
    *libieee802154.a:esp_ieee802154_event.*(.literal.ieee802154_inner_receive_sfd_done .text.ieee802154_inner_receive_sfd_done)
    *libieee802154.a:esp_ieee802154_event.*(.literal.ieee802154_inner_transmit_done .text.ieee802154_inner_transmit_done)
    *libieee802154.a:esp_ieee802154_event.*(.literal.ieee802154_inner_transmit_failed .text.ieee802154_inner_transmit_failed)
    *libieee802154.a:esp_ieee802154_event.*(.literal.ieee802154_inner_transmit_sfd_done .text.ieee802154_inner_transmit_sfd_done)
    *libieee802154.a:esp_ieee802154_frame.*(.literal.ieee802154_frame_get_security_field_len .text.ieee802154_frame_get_security_field_len)
    *libieee802154.a:esp_ieee802154_frame.*(.literal.ieee802154_frame_get_security_payload_offset .text.ieee802154_frame_get_security_payload_offset)
    *libieee802154.a:esp_ieee802154_frame.*(.literal.ieee802154_frame_get_src_addr .text.ieee802154_frame_get_src_addr)
    *libieee802154.a:esp_ieee802154_frame.*(.literal.ieee802154_frame_security_header_offset .text.ieee802154_frame_security_header_offset)
    *libieee802154.a:esp_ieee802154_frame.*(.literal.is_dst_panid_present .text.is_dst_panid_present)
    *libieee802154.a:esp_ieee802154_frame.*(.literal.is_src_panid_present .text.is_src_panid_present)
    *libieee802154.a:esp_ieee802154_pib.*(.literal.ieee802154_pib_get_pending_mode .text.ieee802154_pib_get_pending_mode)
    *libieee802154.a:esp_ieee802154_pib.*(.literal.ieee802154_pib_get_rx_when_idle .text.ieee802154_pib_get_rx_when_idle)
    *libieee802154.a:esp_ieee802154_sec.*(.literal.ieee802154_sec_update .text.ieee802154_sec_update)
    *libieee802154.a:esp_ieee802154_sec.*(.literal.ieee802154_transmit_security_config .text.ieee802154_transmit_security_config)
    *libieee802154.a:esp_ieee802154_timer.*(.literal.ieee802154_timer0_set_threshold .text.ieee802154_timer0_set_threshold)
    *libieee802154.a:esp_ieee802154_timer.*(.literal.ieee802154_timer0_start .text.ieee802154_timer0_start)
    *libieee802154.a:esp_ieee802154_timer.*(.literal.ieee802154_timer0_stop .text.ieee802154_timer0_stop)
    *libieee802154.a:esp_ieee802154_timer.*(.literal.ieee802154_timer1_set_threshold .text.ieee802154_timer1_set_threshold)
    *libieee802154.a:esp_ieee802154_timer.*(.literal.ieee802154_timer1_start .text.ieee802154_timer1_start)
    *libieee802154.a:esp_ieee802154_timer.*(.literal.ieee802154_timer1_stop .text.ieee802154_timer1_stop)
    *libieee802154.a:esp_ieee802154_util.*(.literal.ieee802154_etm_channel_clear .text.ieee802154_etm_channel_clear)

    *components/log/*/log_lock.*(.literal .literal.* .text .text.*)
    *components/log/*/log_timestamp.*(.literal.esp_log_early_timestamp .text.esp_log_early_timestamp)
    *components/log/*/log_timestamp.*(.literal.esp_log_timestamp .text.esp_log_timestamp)
    *components/log/*/log_write.*(.literal.esp_log_write .text.esp_log_write)
    *components/newlib/abort.*(.literal .literal.* .text .text.*)
    *components/newlib/assert.*(.literal .literal.* .text .text.*)
    *components/newlib/heap.*(.literal .literal.* .text .text.*)
    *components/newlib/stdatomic.*(.literal .literal.* .text .text.*)

    *libpp.a:(.wifi0iram .wifi0iram.*)
    *libpp.a:(.wifiextrairam .wifiextrairam.*)
    *libpp.a:(.wifiorslpiram .wifiorslpiram.*)
    *libpp.a:(.wifirxiram .wifirxiram.*)
    *libpp.a:(.wifislpiram .wifislpiram.*)
    *libpp.a:(.wifislprxiram .wifislprxiram.*)

    *components/riscv/interrupt.*(.text .text._global_interrupt_handler .text.intr_get_item .text.intr_handler_get_arg)
    *components/riscv/vectors.*(.literal .literal.* .text .text.*)

    *librtc.a:(.literal .literal.* .text .text.*)

    *components/soc/lldesc.*(.literal .literal.* .text .text.*)
    *components/spi_flash/flash_brownout_hook.*(.literal .literal.* .text .text.*)
    *components/spi_flash/memspi_host_driver.*(.literal .literal.* .text .text.*)
    *components/spi_flash/spi_flash_chip_boya.*(.literal .literal.* .text .text.*)
    *components/spi_flash/spi_flash_chip_gd.*(.literal .literal.* .text .text.*)
    *components/spi_flash/spi_flash_chip_generic.*(.literal .literal.* .text .text.*)
    *components/spi_flash/spi_flash_chip_issi.*(.literal .literal.* .text .text.*)
    *components/spi_flash/spi_flash_chip_mxic.*(.literal .literal.* .text .text.*)
    *components/spi_flash/spi_flash_chip_mxic_opi.*(.literal .literal.* .text .text.*)
    *components/spi_flash/spi_flash_chip_th.*(.literal .literal.* .text .text.*)
    *components/spi_flash/spi_flash_chip_winbond.*(.literal .literal.* .text .text.*)
    *components/spi_flash/spi_flash_wrap.*(.literal .literal.* .text .text.*)

  } > sram_seg

  /* Marks the end of IRAM code segment */
  .iram0.text_end (NOLOAD) :
  {
    /* Align the end of code region as per PMP region granularity */
    . = ALIGN(_esp_pmp_align_size);

    ALIGNED_SYMBOL(4, _iram_text_end)
  } > sram_seg

  .iram0.data :
  {
    ALIGNED_SYMBOL(16, _iram_data_start)

    *(.iram.data .iram.data.*)
    _coredump_iram_start = ABSOLUTE(.);
    *(.iram2.coredump .iram2.coredump.*)
    _coredump_iram_end = ABSOLUTE(.);

    _iram_data_end = ABSOLUTE(.);
  } > sram_seg

  .iram0.bss (NOLOAD) :
  {
    ALIGNED_SYMBOL(16, _iram_bss_start)

    *(.iram.bss .iram.bss.*)

    _iram_bss_end = ABSOLUTE(.);

    ALIGNED_SYMBOL(16, _iram_end)
  } > sram_seg

  .dram0.data :
  {
    _data_start = ABSOLUTE(.);
    *(.gnu.linkonce.d.*)
    *(.data1)
    __global_pointer$ = . + 0x800;
    *(.sdata)
    *(.sdata.*)
    KEEP (*(SORT(.xfa.*)))
    *(.gnu.linkonce.s.*)
    *(.gnu.linkonce.s2.*)
    *(.jcr)

    *(EXCLUDE_FILE(*libble_app.a *libbt.a) .data EXCLUDE_FILE(*libble_app.a *libbt.a) .data.*)
    *(.dram1 .dram1.*)
    /* BEGIN generated from ESP-IDF linker fragments, do not edit */
    *libclang_rt.builtins.a:_divsf3.*(.rodata .rodata.* .sdata2 .sdata2.* .srodata .srodata.*)
    *libclang_rt.builtins.a:restore.*(.rodata .rodata.* .sdata2 .sdata2.* .srodata .srodata.*)
    *libclang_rt.builtins.a:save.*(.rodata .rodata.* .sdata2 .sdata2.* .srodata .srodata.*)
    *components/esp_driver_dma/*esp_dma_utils.*(.rodata.esp_dma_split_rx_buffer_to_cache_aligned .rodata.esp_dma_split_rx_buffer_to_cache_aligned.str1.4 .sdata2.esp_dma_split_rx_buffer_to_cache_aligned .srodata.esp_dma_split_rx_buffer_to_cache_aligned)
    *components/esp_driver_dma/*gdma_link.*(.rodata.gdma_link_mount_buffers .rodata.gdma_link_mount_buffers.str1.4 .sdata2.gdma_link_mount_buffers .srodata.gdma_link_mount_buffers)
    *components/esp_hal_ana_conv/*temperature_sensor_periph.*(.rodata.temperature_sensor_attributes .sdata2.temperature_sensor_attributes .srodata.temperature_sensor_attributes)
    *components/esp_hal_gpspi/*spi_hal_iram.*(.rodata .rodata.* .sdata2 .sdata2.* .srodata .srodata.*)
    *components/esp_hal_gpspi/*spi_slave_hal_iram.*(.rodata .rodata.* .sdata2 .sdata2.* .srodata .srodata.*)
    *components/esp_hal_i2c/*i2c_hal_iram.*(.rodata .rodata.* .sdata2 .sdata2.* .srodata .srodata.*)
    *components/esp_hal_ledc/*ledc_hal_iram.*(.rodata .rodata.* .sdata2 .sdata2.* .srodata .srodata.*)
    *components/esp_hal_mspi/*spi_flash_encrypt_hal_iram.*(.rodata .rodata.* .sdata2 .sdata2.* .srodata .srodata.*)
    *components/esp_hal_mspi/*spi_flash_hal_gpspi.*(.rodata .rodata.* .sdata2 .sdata2.* .srodata .srodata.*)
    *components/esp_hal_mspi/*spi_flash_hal_iram.*(.rodata .rodata.* .sdata2 .sdata2.* .srodata .srodata.*)
    *components/esp_hal_pmu/*pmu_hal.*(.rodata .rodata.* .sdata2 .sdata2.* .srodata .srodata.*)
    *components/esp_hal_regi2c/*.*(.rodata .rodata.* .sdata2 .sdata2.* .srodata .srodata.*)
    *components/esp_hal_systimer/*.*(.rodata .rodata.* .sdata2 .sdata2.* .srodata .srodata.*)
    *components/esp_hal_wdt/*rom_patch.*(.rodata .rodata.* .sdata2 .sdata2.* .srodata .srodata.*)
    *components/esp_hw_support/*adc_share_hw_ctrl.*(.rodata.adc_apb_periph_free .rodata.adc_apb_periph_free.str1.4 .sdata2.adc_apb_periph_free .srodata.adc_apb_periph_free)
    *components/esp_hw_support/*clk_utils.*(.rodata .rodata.* .sdata2 .sdata2.* .srodata .srodata.*)
    *components/esp_hw_support/*cpu.*(.rodata.esp_cpu_reset .rodata.esp_cpu_reset.str1.4 .sdata2.esp_cpu_reset .srodata.esp_cpu_reset)
    *components/esp_hw_support/*esp_clk_tree.*(.rodata.esp_clk_tree_enable_src .rodata.esp_clk_tree_enable_src.str1.4 .sdata2.esp_clk_tree_enable_src .srodata.esp_clk_tree_enable_src)
    *components/esp_hw_support/*esp_memory_utils.*(.rodata .rodata.* .sdata2 .sdata2.* .srodata .srodata.*)
    *components/esp_hw_support/*mspi_timing_tuning.*(.rodata .rodata.* .sdata2 .sdata2.* .srodata .srodata.*)
    *components/esp_hw_support/*pmu_sleep.*(.rodata .rodata.* .sdata2 .sdata2.* .srodata .srodata.*)
    *components/esp_hw_support/*regi2c_ctrl.*(.rodata .rodata.* .sdata2 .sdata2.* .srodata .srodata.*)
    *components/esp_hw_support/*rtc_clk.*(.rodata .rodata.* .sdata2 .sdata2.* .srodata .srodata.*)
    *components/esp_hw_support/*sar_periph_ctrl_common.*(.rodata.regi2c_saradc_disable .rodata.regi2c_saradc_disable.str1.4 .sdata2.regi2c_saradc_disable .srodata.regi2c_saradc_disable)
    *components/esp_hw_support/*sar_tsens_ctrl.*(.rodata.temperature_sensor_power_release .rodata.temperature_sensor_power_release.str1.4 .sdata2.temperature_sensor_power_release .srodata.temperature_sensor_power_release)
    *components/esp_hw_support/*sleep_cache.*(.rodata .rodata.* .sdata2 .sdata2.* .srodata .srodata.*)
    *components/esp_hw_support/*sleep_console.*(.rodata .rodata.* .sdata2 .sdata2.* .srodata .srodata.*)
    *components/esp_hw_support/*sleep_mspi.*(.rodata .rodata.* .sdata2 .sdata2.* .srodata .srodata.*)
    *components/esp_hw_support/*systimer.*(.rodata .rodata.* .sdata2 .sdata2.* .srodata .srodata.*)
    *components/esp_libc/*abort.*(.rodata .rodata.* .sdata2 .sdata2.* .srodata .srodata.*)
    *components/esp_libc/*assert.*(.rodata .rodata.* .sdata2 .sdata2.* .srodata .srodata.*)
    *components/esp_libc/*heap.*(.rodata .rodata.* .sdata2 .sdata2.* .srodata .srodata.*)
    *components/esp_libc/*memcmp.*(.rodata .rodata.* .sdata2 .sdata2.* .srodata .srodata.*)
    *components/esp_libc/*memcpy.*(.rodata .rodata.* .sdata2 .sdata2.* .srodata .srodata.*)
    *components/esp_libc/*memmove.*(.rodata .rodata.* .sdata2 .sdata2.* .srodata .srodata.*)
    *components/esp_libc/*stdatomic.*(.rodata .rodata.* .sdata2 .sdata2.* .srodata .srodata.*)
    *components/esp_libc/*strcmp.*(.rodata .rodata.* .sdata2 .sdata2.* .srodata .srodata.*)
    *components/esp_libc/*strcpy.*(.rodata .rodata.* .sdata2 .sdata2.* .srodata .srodata.*)
    *components/esp_libc/*strncmp.*(.rodata .rodata.* .sdata2 .sdata2.* .srodata .srodata.*)
    *components/esp_libc/*strncpy.*(.rodata .rodata.* .sdata2 .sdata2.* .srodata .srodata.*)
    *components/esp_mm/*esp_cache_msync.*(.rodata .rodata.* .sdata2 .sdata2.* .srodata .srodata.*)
    *components/esp_mm/*esp_cache_utils.*(.rodata .rodata.* .sdata2 .sdata2.* .srodata .srodata.*)
    *components/esp_rom/*esp_rom_print.*(.rodata .rodata.* .sdata2 .sdata2.* .srodata .srodata.*)
    *components/esp_rom/*esp_rom_spiflash.*(.rodata .rodata.* .sdata2 .sdata2.* .srodata .srodata.*)
    *components/esp_rom/*esp_rom_sys.*(.rodata .rodata.* .sdata2 .sdata2.* .srodata .srodata.*)
    *components/esp_system/*esp_err.*(.rodata .rodata.* .sdata2 .sdata2.* .srodata .srodata.*)
    *components/esp_system/*image_process.*(.rodata .rodata.* .sdata2 .sdata2.* .srodata .srodata.*)
    *components/esp_system/*ubsan.*(.rodata .rodata.* .sdata2 .sdata2.* .srodata .srodata.*)
    *libgcc.a:_divsf3.*(.rodata .rodata.* .sdata2 .sdata2.* .srodata .srodata.*)
    *libgcc.a:save-restore.*(.rodata .rodata.* .sdata2 .sdata2.* .srodata .srodata.*)
    *libgcov.a:(.rodata .rodata.* .sdata2 .sdata2.* .srodata .srodata.*)
    *components/hal/*cache_hal.*(.rodata .rodata.* .sdata2 .sdata2.* .srodata .srodata.*)
    *components/hal/*mmu_hal.*(.rodata .rodata.* .sdata2 .sdata2.* .srodata .srodata.*)
    *components/ieee802154/*esp_ieee802154.*(.rodata.esp_ieee802154_enh_ack_generator .rodata.esp_ieee802154_enh_ack_generator.str1.4 .sdata2.esp_ieee802154_enh_ack_generator .srodata.esp_ieee802154_enh_ack_generator)
    *components/ieee802154/*esp_ieee802154_ack.*(.rodata.ieee802154_ack_config_pending_bit .rodata.ieee802154_ack_config_pending_bit.str1.4 .sdata2.ieee802154_ack_config_pending_bit .srodata.ieee802154_ack_config_pending_bit)
    *components/ieee802154/*esp_ieee802154_frame.*(.rodata.ieee802154_frame_get_dst_addr .rodata.ieee802154_frame_get_dst_addr.str1.4 .sdata2.ieee802154_frame_get_dst_addr .srodata.ieee802154_frame_get_dst_addr)
    *components/ieee802154/*esp_ieee802154_frame.*(.rodata.ieee802154_frame_get_security_field_len .rodata.ieee802154_frame_get_security_field_len.str1.4 .sdata2.ieee802154_frame_get_security_field_len .srodata.ieee802154_frame_get_security_field_len)
    *components/ieee802154/*esp_ieee802154_frame.*(.rodata.ieee802154_frame_security_header_offset .rodata.ieee802154_frame_security_header_offset.str1.4 .sdata2.ieee802154_frame_security_header_offset .srodata.ieee802154_frame_security_header_offset)
    *components/ieee802154/*esp_ieee802154_sec.*(.rodata.ieee802154_transmit_security_config .rodata.ieee802154_transmit_security_config.str1.4 .sdata2.ieee802154_transmit_security_config .srodata.ieee802154_transmit_security_config)
    *components/log/*log.*(.rodata .rodata.* .sdata2 .sdata2.* .srodata .srodata.*)
    *components/log/*log_format_text.*(.rodata .rodata.* .sdata2 .sdata2.* .srodata .srodata.*)
    *components/log/*log_lock.*(.rodata .rodata.* .sdata2 .sdata2.* .srodata .srodata.*)
    *components/log/*log_print.*(.rodata .rodata.* .sdata2 .sdata2.* .srodata .srodata.*)
    *components/log/*log_timestamp_common.*(.rodata .rodata.* .sdata2 .sdata2.* .srodata .srodata.*)
    *components/log/*util.*(.rodata .rodata.* .sdata2 .sdata2.* .srodata .srodata.*)
    *libphy.a:(.rodata .rodata.* .sdata2 .sdata2.* .srodata .srodata.*)
    *components/soc/*lldesc.*(.rodata .rodata.* .sdata2 .sdata2.* .srodata .srodata.*)
    *components/spi_flash/*flash_brownout_hook.*(.rodata .rodata.* .sdata2 .sdata2.* .srodata .srodata.*)
    *components/spi_flash/*memspi_host_driver.*(.rodata .rodata.* .sdata2 .sdata2.* .srodata .srodata.*)
    *components/spi_flash/*spi_flash_chip_boya.*(.rodata .rodata.* .sdata2 .sdata2.* .srodata .srodata.*)
    *components/spi_flash/*spi_flash_chip_gd.*(.rodata .rodata.* .sdata2 .sdata2.* .srodata .srodata.*)
    *components/spi_flash/*spi_flash_chip_generic.*(.rodata .rodata.* .sdata2 .sdata2.* .srodata .srodata.*)
    *components/spi_flash/*spi_flash_chip_issi.*(.rodata .rodata.* .sdata2 .sdata2.* .srodata .srodata.*)
    *components/spi_flash/*spi_flash_chip_mxic.*(.rodata .rodata.* .sdata2 .sdata2.* .srodata .srodata.*)
    *components/spi_flash/*spi_flash_chip_th.*(.rodata .rodata.* .sdata2 .sdata2.* .srodata .srodata.*)
    *components/spi_flash/*spi_flash_chip_winbond.*(.rodata .rodata.* .sdata2 .sdata2.* .srodata .srodata.*)
    *components/spi_flash/*spi_flash_os_func_app.*(.rodata.get_buffer_malloc .rodata.get_buffer_malloc.str1.4 .sdata2.get_buffer_malloc .srodata.get_buffer_malloc)
    *components/spi_flash/*spi_flash_wrap.*(.rodata .rodata.* .sdata2 .sdata2.* .srodata .srodata.*)
    /* END generated from ESP-IDF linker fragments */
    _coredump_dram_start = ABSOLUTE(.);
    *(.dram2.coredump .dram2.coredump.*)
    _coredump_dram_end = ABSOLUTE(.);
    *components/app_trace/app_trace.*(.rodata .rodata.* .sdata2 .sdata2.* .srodata .srodata.*)
    *components/app_trace/app_trace_util.*(.rodata .rodata.* .sdata2 .sdata2.* .srodata .srodata.*)
    *components/app_trace/port_uart.*(.rodata .rodata.* .sdata2 .sdata2.* .srodata .srodata.*)

    . = ALIGN(4);
    _bt_controller_data_start = ABSOLUTE(.);
    *libble_app.a:(.data .data.*)
    . = ALIGN(4);
    _bt_controller_data_end = ABSOLUTE(.);
    . = ALIGN(4);
    _bt_data_start = ABSOLUTE(.);
    *libbt.a:(.data .data.*)
    . = ALIGN(4);
    _bt_data_end = ABSOLUTE(.);

    *components/esp_hw_support/esp_memory_utils.*(.rodata .rodata.* .sdata2 .sdata2.* .srodata .srodata.*)
    *components/esp_hw_support/mspi_timing_tuning.*(.rodata .rodata.* .sdata2 .sdata2.* .srodata .srodata.*)
    *components/esp_hw_support/*/pmu_sleep.*(.rodata .rodata.* .sdata2 .sdata2.* .srodata .srodata.*)
    *components/esp_hw_support/*/rtc_clk.*(.rodata .rodata.* .sdata2 .sdata2.* .srodata .srodata.*)
    *components/esp_hw_support/sleep_console.*(.rodata .rodata.* .sdata2 .sdata2.* .srodata .srodata.*)
    *components/esp_hw_support/*/systimer.*(.rodata .rodata.* .sdata2 .sdata2.* .srodata .srodata.*)
    *components/esp_mm/esp_cache.*(.rodata .rodata.* .sdata2 .sdata2.* .srodata .srodata.*)
    *components/esp_rom/patches/esp_rom_print.*(.rodata .rodata.* .sdata2 .sdata2.* .srodata .srodata.*)
    *components/esp_rom/patches/esp_rom_spiflash.*(.rodata .rodata.* .sdata2 .sdata2.* .srodata .srodata.*)
    *components/esp_rom/patches/esp_rom_sys.*(.rodata .rodata.* .sdata2 .sdata2.* .srodata .srodata.*)
    *components/esp_rom/patches/esp_rom_systimer.*(.rodata .rodata.* .sdata2 .sdata2.* .srodata .srodata.*)
    *components/esp_rom/patches/esp_rom_tlsf.*(.rodata .rodata.* .sdata2 .sdata2.* .srodata .srodata.*)
    *components/esp_rom/patches/esp_rom_wdt.*(.rodata .rodata.* .sdata2 .sdata2.* .srodata .srodata.*)
    *components/esp_system/esp_err.*(.rodata .rodata.* .sdata2 .sdata2.* .srodata .srodata.*)
    *components/esp_system/port/image_process.*(.rodata .rodata.* .sdata2 .sdata2.* .srodata .srodata.*)
    *components/esp_system/ubsan.*(.rodata .rodata.* .sdata2 .sdata2.* .srodata .srodata.*)

    *libclang_rt.builtins.a:_divsf3.*(.rodata .rodata.* .sdata2 .sdata2.* .srodata .srodata.*)
    *libclang_rt.builtins.a:restore.*(.rodata .rodata.* .sdata2 .sdata2.* .srodata .srodata.*)
    *libclang_rt.builtins.a:save.*(.rodata .rodata.* .sdata2 .sdata2.* .srodata .srodata.*)
    *libgcc.a:_divsf3.*(.rodata .rodata.* .sdata2 .sdata2.* .srodata .srodata.*)
    *libgcc.a:save-restore.*(.rodata .rodata.* .sdata2 .sdata2.* .srodata .srodata.*)
    *libgcov.a:(.rodata .rodata.* .sdata2 .sdata2.* .srodata .srodata.*)
    *libg_nano.a:libc_a-mem*(.literal .literal.* .text .text.*)

    *components/hal/cache_hal.*(.rodata .rodata.* .sdata2 .sdata2.* .srodata .srodata.*)
    *components/hal/i2c_hal_iram.*(.rodata .rodata.* .sdata2 .sdata2.* .srodata .srodata.*)
    *components/hal/ledc_hal_iram.*(.rodata .rodata.* .sdata2 .sdata2.* .srodata .srodata.*)
    *components/hal/mmu_hal.*(.rodata .rodata.* .sdata2 .sdata2.* .srodata .srodata.*)
    *components/hal/pmu_hal.*(.rodata .rodata.* .sdata2 .sdata2.* .srodata .srodata.*)
    *components/hal/spi_flash_encrypt_hal_iram.*(.rodata .rodata.* .sdata2 .sdata2.* .srodata .srodata.*)
    *components/hal/spi_flash_hal_gpspi.*(.rodata .rodata.* .sdata2 .sdata2.* .srodata .srodata.*)
    *components/hal/spi_flash_hal_iram.*(.rodata .rodata.* .sdata2 .sdata2.* .srodata .srodata.*)
    *components/hal/spi_hal_iram.*(.rodata .rodata.* .sdata2 .sdata2.* .srodata .srodata.*)
    *components/hal/spi_slave_hal_iram.*(.rodata .rodata.* .sdata2 .sdata2.* .srodata .srodata.*)
    *components/hal/wdt_hal_iram.*(.rodata .rodata.* .sdata2 .sdata2.* .srodata .srodata.*)
    *components/log/*/log_lock.*(.rodata .rodata.* .sdata2 .sdata2.* .srodata .srodata.*)

    *components/newlib/abort.*(.rodata .rodata.* .sdata2 .sdata2.* .srodata .srodata.*)
    *components/newlib/assert.*(.rodata .rodata.* .sdata2 .sdata2.* .srodata .srodata.*)
    *components/newlib/heap.*(.rodata .rodata.* .sdata2 .sdata2.* .srodata .srodata.*)
    *components/newlib/stdatomic.*(.rodata .rodata.* .sdata2 .sdata2.* .srodata .srodata.*)

    _nimble_data_start = ABSOLUTE(.);
    *libnimble.a:(.data .data.*)
    . = ALIGN(4);
    _nimble_data_end = ABSOLUTE(.);

    *libphy.a:(.rodata .rodata.* .sdata2 .sdata2.* .srodata .srodata.*)

    *components/soc/lldesc.*(.rodata .rodata.* .sdata2 .sdata2.* .srodata .srodata.*)
    *components/spi_flash/flash_brownout_hook.*(.rodata .rodata.* .sdata2 .sdata2.* .srodata .srodata.*)
    *components/spi_flash/memspi_host_driver.*(.rodata .rodata.* .sdata2 .sdata2.* .srodata .srodata.*)
    *components/spi_flash/spi_flash_chip_boya.*(.rodata .rodata.* .sdata2 .sdata2.* .srodata .srodata.*)
    *components/spi_flash/spi_flash_chip_gd.*(.rodata .rodata.* .sdata2 .sdata2.* .srodata .srodata.*)
    *components/spi_flash/spi_flash_chip_generic.*(.rodata .rodata.* .sdata2 .sdata2.* .srodata .srodata.*)
    *components/spi_flash/spi_flash_chip_issi.*(.rodata .rodata.* .sdata2 .sdata2.* .srodata .srodata.*)
    *components/spi_flash/spi_flash_chip_mxic.*(.rodata .rodata.* .sdata2 .sdata2.* .srodata .srodata.*)
    *components/spi_flash/spi_flash_chip_mxic_opi.*(.rodata .rodata.* .sdata2 .sdata2.* .srodata .srodata.*)
    *components/spi_flash/spi_flash_chip_th.*(.rodata .rodata.* .sdata2 .sdata2.* .srodata .srodata.*)
    *components/spi_flash/spi_flash_chip_winbond.*(.rodata .rodata.* .sdata2 .sdata2.* .srodata .srodata.*)
    *components/spi_flash/spi_flash_wrap.*(.rodata .rodata.* .sdata2 .sdata2.* .srodata .srodata.*)

    _data_end = ABSOLUTE(.);
  } > sram_seg

  /**
   * This section holds data that should not be initialized at power up.
   * The section located in Internal SRAM memory region. The macro _NOINIT
   * can be used as attribute to place data into this section.
   * See the "esp_attr.h" file for more information.
   */
  .noinit (NOLOAD):
  {
    ALIGNED_SYMBOL(4, _noinit_start)

    *(.noinit .noinit.*)

    ALIGNED_SYMBOL(4, _noinit_end)
  } > sram_seg

  /* Shared RAM */
  .dram0.bss (NOLOAD) :
  {
    ALIGNED_SYMBOL(8, _bss_start)

    /**
     * ldgen places all bss-related data to mapping[dram0_bss]
     * (See components/esp_system/app.lf).
     */
    *(EXCLUDE_FILE(*libble_app.a *libbt.a) .bss EXCLUDE_FILE(*libble_app.a *libbt.a) .bss.*)
    *(.dynbss .dynsbss .gnu.linkonce.b .gnu.linkonce.b.* .gnu.linkonce.sb .gnu.linkonce.sb.* .gnu.linkonce.sb2 .gnu.linkonce.sb2.* .sbss .sbss.* .sbss2 .sbss2.* .scommon .share.mem)
    *(.ext_ram.bss .ext_ram.bss.*)
    *(EXCLUDE_FILE(*libble_app.a *libbt.a) COMMON)
    . = ALIGN(4);
    _bt_controller_bss_start = ABSOLUTE(.);
    *libble_app.a:(.bss .bss.*)
    . = ALIGN(4);
    _bt_controller_bss_end = ABSOLUTE(.);
    . = ALIGN(4);
    _bt_controller_common_start = ABSOLUTE(.);
    *libble_app.a:(COMMON)
    . = ALIGN(4);
    _bt_controller_common_end = ABSOLUTE(.);
    . = ALIGN(4);
    _bt_bss_start = ABSOLUTE(.);
    *libbt.a:(.bss .bss.*)
    . = ALIGN(4);
    _bt_bss_end = ABSOLUTE(.);
    . = ALIGN(4);
    _bt_common_start = ABSOLUTE(.);
    *libbt.a:(COMMON)
    . = ALIGN(4);
    _bt_common_end = ABSOLUTE(.);

    ALIGNED_SYMBOL(8, _bss_end)
  } > sram_seg

  .flash.text :
  {
    _stext = .;
    /**
     * Mark the start of flash.text.
     * This can be used by the MMU driver to maintain the virtual address.
     */
    _instruction_reserved_start = ABSOLUTE(.);
    _text_start = ABSOLUTE(.);

    *(.literal .literal.* .text .text.*)
    *(.wifi0iram .wifi0iram.*)
    *(.wifiextrairam .wifiextrairam.*)
    *(.wifiorslpiram .wifiorslpiram.*)
    *(.wifirxiram .wifirxiram.*)
    *(.wifislpiram .wifislpiram.*)
    *(.wifislprxiram .wifislprxiram.*)
    /* BLE controller code placed in flash (linker_esp_ble_controller.lf) */
    *(.adv_fast_execute_code_iram1 .adv_fast_execute_code_iram1.*)
    *(.iram_sleep .iram_sleep.* .iram_btslp .iram_btslp.*)
    *(.iram_sleep_adv .iram_sleep_adv.* .iram_sleep_conn .iram_sleep_conn.*)

    *(.stub)
    *(.gnu.linkonce.t.*)
    *(.gnu.warning)
    *(.irom0.text) /* catch stray ICACHE_RODATA_ATTR */

    /**
     * CPU will try to prefetch up to 16 bytes of of instructions.
     * This means that any configuration (e.g. MMU, PMS) must allow
     * safe access to up to 16 bytes after the last real instruction, add
     * dummy bytes to ensure this
     */
    . += _esp_flash_mmap_prefetch_pad_size;

    _text_end = ABSOLUTE(.);
    /**
     * Mark the flash.text end.
     * This can be used for MMU driver to maintain virtual address.
     */
    _instruction_reserved_end = ABSOLUTE(.);
    _etext = .;

    /**
     * Similar to _iram_start, this symbol goes here so it is
     * resolved by addr2line in preference to the first symbol in
     * the flash.text segment.
     */
    _flash_cache_start = ABSOLUTE(0);
  } > default_code_seg

  /**
   * Dummy section represents the .flash.text section but in default_rodata_seg.
   * Thus, it must have its alignment and (at least) its size.
   */
  .flash_rodata_dummy (NOLOAD):
  {
    _flash_rodata_dummy_start = .;

    . = ALIGN(ALIGNOF(.flash.text)) + SIZEOF(.flash.text);

    /* Add alignment of MMU page size + 0x20 bytes for the mapping header. */
    . = ALIGN(_esp_mmu_page_size) + 0x20;
  } > default_rodata_seg

  .flash.appdesc : ALIGN(0x10)
  {
    /**
     * Mark flash.rodata start.
     * This can be used for mmu driver to maintain virtual address
     */
    _rodata_reserved_start = ABSOLUTE(.);
    _rodata_start = ABSOLUTE(.);

    /* !DO NOT PUT ANYTHING BEFORE THIS! */

    /* Should be the first.  App version info. */
    *(.rodata_desc .rodata_desc.*)
    /* Should be the second. Custom app version info. */
    *(.rodata_custom_desc .rodata_custom_desc.*)

    /**
     * Create an empty gap within this section. Thanks to this, the end of this
     * section will match .flash.rodata's begin address. Thus, both sections
     * will be merged when creating the final bin image.
     */
    . = ALIGN(ALIGNOF(.flash.rodata));
  } > default_rodata_seg
  ASSERT_SECTIONS_GAP(.flash.appdesc, .flash.rodata)

  .flash.rodata : ALIGN(0x10)
  {
    _flash_rodata_start = ABSOLUTE(.);

    *(.rodata .rodata.* .sdata2 .sdata2.* .srodata .srodata.*)
    *(.rodata_wlog_error .rodata_wlog_error.*)
    *(.rodata_wlog_info .rodata_wlog_info.*)
    *(.rodata_wlog_warning .rodata_wlog_warning.*)
    *(.rodata_wlog_debug .rodata_wlog_debug.*)
    *(.rodata_wlog_verbose .rodata_wlog_verbose.*)

    KEEP (*(SORT(.roxfa.*)))

    *(.irom1.text) /* catch stray ICACHE_RODATA_ATTR */
    *(.gnu.linkonce.r.*)
    *(.rodata1)
    *(.gcc_except_table .gcc_except_table.*)
    *(.gnu.linkonce.e.*)
    /**
     * C++ constructor tables.
     *
     * Excluding crtbegin.o/crtend.o since IDF doesn't use the toolchain crt.
     *
     * RISC-V gcc is configured with --enable-initfini-array so it emits
     * .init_array section instead. But the init_priority sections will be
     * sorted for iteration in ascending order during startup.
     * The rest of the init_array sections is sorted for iteration in descending
     * order during startup, however. Hence a different section is generated for
     * the init_priority functions which is iterated in ascending order during
     * startup. The corresponding code can be found in startup.c.
     */
    ALIGNED_SYMBOL(4, __init_priority_array_start)
    KEEP (*(EXCLUDE_FILE (*crtend.* *crtbegin.*) .init_array.*))
    __init_priority_array_end = ABSOLUTE(.);

    ALIGNED_SYMBOL(4, __init_array_start)
    KEEP (*(EXCLUDE_FILE (*crtend.* *crtbegin.*) .init_array))
    __init_array_end = ABSOLUTE(.);

    /* Addresses of memory regions reserved via SOC_RESERVE_MEMORY_REGION() */
    ALIGNED_SYMBOL(4, soc_reserved_memory_region_start)
    KEEP (*(.reserved_memory_address))
    soc_reserved_memory_region_end = ABSOLUTE(.);

    /* System init functions registered via ESP_SYSTEM_INIT_FN */
    ALIGNED_SYMBOL(4, _esp_system_init_fn_array_start)
    KEEP (*(SORT_BY_INIT_PRIORITY(.esp_system_init_fn.*)))
    _esp_system_init_fn_array_end = ABSOLUTE(.);

    _rodata_end = ABSOLUTE(.);
    . = ALIGN(ALIGNOF(.eh_frame_hdr));
  } > default_rodata_seg
  ASSERT_SECTIONS_GAP(.flash.rodata, .eh_frame_hdr)

  .eh_frame_hdr :
  {
#if CONFIG_COMPILER_CXX_EXCEPTIONS || CONFIG_ESP_SYSTEM_USE_EH_FRAME
    ALIGNED_SYMBOL(4, __eh_frame_hdr)

    KEEP (*(.eh_frame_hdr))

    __eh_frame_hdr_end = ABSOLUTE(.);
#endif // CONFIG_COMPILER_CXX_EXCEPTIONS || CONFIG_ESP_SYSTEM_USE_EH_FRAME

    . = ALIGN(ALIGNOF(.eh_frame));
  } > default_rodata_seg
  ASSERT_SECTIONS_GAP(.eh_frame_hdr, .eh_frame)

  .eh_frame :
  {
#if CONFIG_COMPILER_CXX_EXCEPTIONS || CONFIG_ESP_SYSTEM_USE_EH_FRAME
    ALIGNED_SYMBOL(4, __eh_frame)

    KEEP (*(.eh_frame))
    /**
     * As we are not linking with crtend.o, which includes the CIE terminator
     * (see __FRAME_END__ in libgcc sources), it is manually provided here.
     */
    LONG(0);

    __eh_frame_end = ABSOLUTE(.);
#endif // CONFIG_COMPILER_CXX_EXCEPTIONS || CONFIG_ESP_SYSTEM_USE_EH_FRAME

    . = ALIGN(ALIGNOF(.flash.tdata));
  } > default_rodata_seg
  ASSERT_SECTIONS_GAP(.eh_frame, .flash.tdata)

  .flash.tdata :
  {
    _thread_local_data_start = ABSOLUTE(.);

    *(.tdata .tdata.* .gnu.linkonce.td.*)

    . = ALIGN(ALIGNOF(.flash.tbss));
    _thread_local_data_end = ABSOLUTE(.);
  } > default_rodata_seg
  ASSERT_SECTIONS_GAP(.flash.tdata, .flash.tbss)

  .flash.tbss (NOLOAD) :
  {
    _thread_local_bss_start = ABSOLUTE(.);

    *(.tbss .tbss.* .gnu.linkonce.tb.*)
    *(.tcommon .tcommon.*)

    _thread_local_bss_end = ABSOLUTE(.);
  } > default_rodata_seg

  /**
   * This section contains all the rodata that is not used
   * at runtime, helping to avoid an increase in binary size.
   */
  .flash.rodata_noload (NOLOAD) :
  {
    /**
     * This symbol marks the end of flash.rodata. It can be utilized by the MMU
     * driver to maintain the virtual address.
     * NOLOAD rodata may not be included in this section.
     */
    _rodata_reserved_end = ADDR(.flash.tbss);

    . = ALIGN(CONFIG_MMU_PAGE_SIZE);
    _fp_mmu_start = .;
    _fp_mmu_end = . + CONFIG_ESP_FLASHPAGE_CAPACITY;

    _fp_mem_start = . ;
    KEEP(*(SORT(.flash_writable.*)))
    _fp_mem_end = . ;
    . = ALIGN(4096);
    _end_fw = . ;

    *(.rodata_wlog_debug .rodata_wlog_debug.*)
    *(.rodata_wlog_verbose .rodata_wlog_verbose.*)
  } > default_rodata_seg

  /* Marks the end of data, bss and possibly rodata */
  .dram0.heap_start (NOLOAD) :
  {
    ALIGNED_SYMBOL(16, _heap_start)
    _sheap = ABSOLUTE(.);
  } > sram_seg

  . = ORIGIN(sram_seg) + LENGTH(sram_seg);
  _eheap = ABSOLUTE(.);

#include "elf_misc.ld.in"
}
